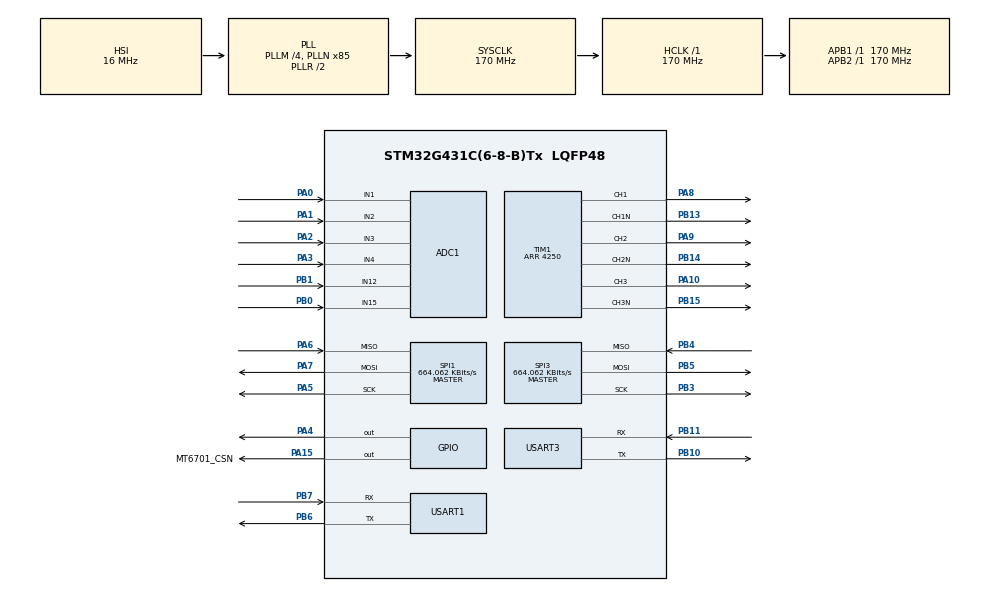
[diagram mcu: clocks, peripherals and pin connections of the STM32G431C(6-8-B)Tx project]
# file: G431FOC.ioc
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ADC1.Channel-0\#ChannelRegularConversion=ADC_CHANNEL_4
ADC1.Channel-4\#ChannelRegularConversion=ADC_CHANNEL_12
ADC1.Channel-5\#ChannelRegularConversion=ADC_CHANNEL_15
ADC1.ContinuousConvMode=ENABLE
ADC1.EOCSelection=ADC_EOC_SEQ_CONV
ADC1.EnableInjectedConversion=ENABLE
ADC1.ExternalTrigInjecConv=ADC_EXTERNALTRIGINJEC_T1_TRGO
ADC1.InjNumberOfConversion=2
ADC1.InjectedChannel-1\#ChannelInjectedConversion=ADC_CHANNEL_1
ADC1.InjectedChannel-2\#ChannelInjectedConversion=ADC_CHANNEL_2
ADC1.InjectedOffsetNumber-1\#ChannelInjectedConversion=ADC_OFFSET_NONE
ADC1.InjectedOffsetNumber-2\#ChannelInjectedConversion=ADC_OFFSET_NONE
ADC1.InjectedRank-1\#ChannelInjectedConversion=1
ADC1.InjectedRank-2\#ChannelInjectedConversion=2
ADC1.InjectedSamplingTime-1\#ChannelInjectedConversion=ADC_SAMPLETIME_47CYCLES_5
ADC1.InjectedSamplingTime-2\#ChannelInjectedConversion=ADC_SAMPLETIME_47CYCLES_5
ADC1.NbrOfConversion=3
ADC1.NbrOfConversionFlag=1
ADC1.OffsetNumber-0\#ChannelRegularConversion=ADC_OFFSET_NONE
ADC1.OffsetNumber-4\#ChannelRegularConversion=ADC_OFFSET_NONE
ADC1.OffsetNumber-5\#ChannelRegularConversion=ADC_OFFSET_NONE
ADC1.Rank-0\#ChannelRegularConversion=1
ADC1.Rank-4\#ChannelRegularConversion=2
ADC1.Rank-5\#ChannelRegularConversion=3
ADC1.SamplingTime-0\#ChannelRegularConversion=ADC_SAMPLETIME_47CYCLES_5
ADC1.SamplingTime-4\#ChannelRegularConversion=ADC_SAMPLETIME_47CYCLES_5
ADC1.SamplingTime-5\#ChannelRegularConversion=ADC_SAMPLETIME_47CYCLES_5
ADC1.master=1
Dma.ADC1.0.Direction=DMA_PERIPH_TO_MEMORY
Dma.ADC1.0.EventEnable=DISABLE
Dma.ADC1.0.Instance=DMA1_Channel1
Dma.ADC1.0.MemDataAlignment=DMA_MDATAALIGN_HALFWORD
Dma.ADC1.0.MemInc=DMA_MINC_ENABLE
Dma.ADC1.0.Mode=DMA_CIRCULAR
Dma.ADC1.0.PeriphDataAlignment=DMA_PDATAALIGN_HALFWORD
Dma.ADC1.0.PeriphInc=DMA_PINC_DISABLE
Dma.ADC1.0.Polarity=HAL_DMAMUX_REQ_GEN_RISING
Dma.ADC1.0.Priority=DMA_PRIORITY_LOW
Dma.ADC1.0.RequestNumber=1
Dma.ADC1.0.SignalID=NONE
Dma.ADC1.0.SyncEnable=DISABLE
Dma.ADC1.0.SyncPolarity=HAL_DMAMUX_SYNC_NO_EVENT
Dma.ADC1.0.SyncRequestNumber=1
Dma.ADC1.0.SyncSignalID=NONE
Dma.Request0=ADC1
Dma.Request1=SPI1_RX
Dma.Request2=SPI1_TX
Dma.Request3=SPI3_RX
Dma.Request4=SPI3_TX
Dma.SPI1_RX.1.Direction=DMA_PERIPH_TO_MEMORY
Dma.SPI1_RX.1.EventEnable=DISABLE
Dma.SPI1_RX.1.Instance=DMA1_Channel2
Dma.SPI1_RX.1.MemDataAlignment=DMA_MDATAALIGN_BYTE
Dma.SPI1_RX.1.MemInc=DMA_MINC_ENABLE
Dma.SPI1_RX.1.Mode=DMA_NORMAL
Dma.SPI1_RX.1.PeriphDataAlignment=DMA_PDATAALIGN_BYTE
Dma.SPI1_RX.1.PeriphInc=DMA_PINC_DISABLE
Dma.SPI1_RX.1.Polarity=HAL_DMAMUX_REQ_GEN_RISING
Dma.SPI1_RX.1.Priority=DMA_PRIORITY_LOW
Dma.SPI1_RX.1.RequestNumber=1
Dma.SPI1_RX.1.SignalID=NONE
Dma.SPI1_RX.1.SyncEnable=DISABLE
Dma.SPI1_RX.1.SyncPolarity=HAL_DMAMUX_SYNC_NO_EVENT
Dma.SPI1_RX.1.SyncRequestNumber=1
Dma.SPI1_RX.1.SyncSignalID=NONE
Dma.SPI1_TX.2.Direction=DMA_MEMORY_TO_PERIPH
Dma.SPI1_TX.2.EventEnable=DISABLE
Dma.SPI1_TX.2.Instance=DMA1_Channel3
Dma.SPI1_TX.2.MemDataAlignment=DMA_MDATAALIGN_BYTE
Dma.SPI1_TX.2.MemInc=DMA_MINC_ENABLE
Dma.SPI1_TX.2.Mode=DMA_NORMAL
Dma.SPI1_TX.2.PeriphDataAlignment=DMA_PDATAALIGN_BYTE
Dma.SPI1_TX.2.PeriphInc=DMA_PINC_DISABLE
Dma.SPI1_TX.2.Polarity=HAL_DMAMUX_REQ_GEN_RISING
Dma.SPI1_TX.2.Priority=DMA_PRIORITY_LOW
Dma.SPI1_TX.2.RequestNumber=1
Dma.SPI1_TX.2.SignalID=NONE
Dma.SPI1_TX.2.SyncEnable=DISABLE
Dma.SPI1_TX.2.SyncPolarity=HAL_DMAMUX_SYNC_NO_EVENT
Dma.SPI1_TX.2.SyncRequestNumber=1
Dma.SPI1_TX.2.SyncSignalID=NONE
Dma.SPI3_RX.3.Direction=DMA_PERIPH_TO_MEMORY
Dma.SPI3_RX.3.EventEnable=DISABLE
Dma.SPI3_RX.3.Instance=DMA1_Channel4
Dma.SPI3_RX.3.MemDataAlignment=DMA_MDATAALIGN_BYTE
Dma.SPI3_RX.3.MemInc=DMA_MINC_ENABLE
Dma.SPI3_RX.3.Mode=DMA_NORMAL
Dma.SPI3_RX.3.PeriphDataAlignment=DMA_PDATAALIGN_BYTE
Dma.SPI3_RX.3.PeriphInc=DMA_PINC_DISABLE
Dma.SPI3_RX.3.Polarity=HAL_DMAMUX_REQ_GEN_RISING
Dma.SPI3_RX.3.Priority=DMA_PRIORITY_LOW
Dma.SPI3_RX.3.RequestNumber=1
Dma.SPI3_RX.3.SignalID=NONE
Dma.SPI3_RX.3.SyncEnable=DISABLE
Dma.SPI3_RX.3.SyncPolarity=HAL_DMAMUX_SYNC_NO_EVENT
Dma.SPI3_RX.3.SyncRequestNumber=1
Dma.SPI3_RX.3.SyncSignalID=NONE
Dma.SPI3_TX.4.Direction=DMA_MEMORY_TO_PERIPH
Dma.SPI3_TX.4.EventEnable=DISABLE
Dma.SPI3_TX.4.Instance=DMA1_Channel5
Dma.SPI3_TX.4.MemDataAlignment=DMA_MDATAALIGN_BYTE
Dma.SPI3_TX.4.MemInc=DMA_MINC_ENABLE
Dma.SPI3_TX.4.Mode=DMA_NORMAL
Dma.SPI3_TX.4.PeriphDataAlignment=DMA_PDATAALIGN_BYTE
Dma.SPI3_TX.4.PeriphInc=DMA_PINC_DISABLE
Dma.SPI3_TX.4.Polarity=HAL_DMAMUX_REQ_GEN_RISING
Dma.SPI3_TX.4.Priority=DMA_PRIORITY_LOW
Dma.SPI3_TX.4.RequestNumber=1
Dma.SPI3_TX.4.SignalID=NONE
Dma.SPI3_TX.4.SyncEnable=DISABLE
Dma.SPI3_TX.4.SyncPolarity=HAL_DMAMUX_SYNC_NO_EVENT
Dma.SPI3_TX.4.SyncRequestNumber=1
Dma.SPI3_TX.4.SyncSignalID=NONE
Mcu.Family=STM32G4
Mcu.Name=STM32G431C(6-8-B)Tx
Mcu.Package=LQFP48
NVIC.ADC1_2_IRQn=true\:0\:0\:false\:false\:true\:true\:true\:true
NVIC.DMA1_Channel1_IRQn=true\:0\:0\:false\:false\:true\:false\:true\:true
NVIC.DMA1_Channel2_IRQn=true\:1\:0\:false\:false\:true\:false\:true\:true
NVIC.DMA1_Channel3_IRQn=true\:1\:0\:false\:false\:true\:false\:true\:true
NVIC.DMA1_Channel4_IRQn=true\:1\:0\:false\:false\:true\:false\:true\:true
NVIC.DMA1_Channel5_IRQn=true\:1\:0\:false\:false\:true\:false\:true\:true
NVIC.PriorityGroup=NVIC_PRIORITYGROUP_4
NVIC.SPI1_IRQn=true\:1\:0\:false\:false\:true\:true\:true\:true
NVIC.SPI3_IRQn=true\:1\:0\:false\:false\:true\:true\:true\:true
NVIC.TIM2_IRQn=true\:0\:0\:false\:false\:true\:true\:true\:true
PA0.Mode=IN1-Single-Ended
PA0.Signal=ADC1_IN1
PA1.Mode=IN2-Single-Ended
PA1.Signal=ADC1_IN2
PA10.Signal=S_TIM1_CH3
PA13.Mode=Serial_Wire
PA13.Signal=SYS_JTMS-SWDIO
PA14.Mode=Serial_Wire
PA14.Signal=SYS_JTCK-SWCLK
PA15.GPIO_Label=MT6701_CSN
PA15.PinState=GPIO_PIN_SET
PA15.Signal=GPIO_Output
PA2.Mode=IN3-Single-Ended
PA2.Signal=ADC1_IN3
PA3.Mode=IN4-Single-Ended
PA3.Signal=ADC1_IN4
PA4.PinState=GPIO_PIN_SET
PA4.Signal=GPIO_Output
PA5.Mode=Full_Duplex_Master
PA5.Signal=SPI1_SCK
PA6.Mode=Full_Duplex_Master
PA6.Signal=SPI1_MISO
PA7.Mode=Full_Duplex_Master
PA7.Signal=SPI1_MOSI
PA8.Signal=S_TIM1_CH1
PA9.Signal=S_TIM1_CH2
PB0.Mode=IN15-Single-Ended
PB0.Signal=ADC1_IN15
PB1.Mode=IN12-Single-Ended
PB1.Signal=ADC1_IN12
PB10.Mode=Asynchronous
PB10.Signal=USART3_TX
PB11.Mode=Asynchronous
PB11.Signal=USART3_RX
PB13.Mode=PWM Generation1 CH1 CH1N
PB13.Signal=TIM1_CH1N
PB14.Mode=PWM Generation2 CH2 CH2N
PB14.Signal=TIM1_CH2N
PB15.Mode=PWM Generation3 CH3 CH3N
PB15.Signal=TIM1_CH3N
PB3.Mode=Full_Duplex_Master
PB3.Signal=SPI3_SCK
PB4.Mode=Full_Duplex_Master
PB4.Signal=SPI3_MISO
PB5.Mode=Full_Duplex_Master
PB5.Signal=SPI3_MOSI
PB6.Mode=Asynchronous
PB6.Signal=USART1_TX
PB7.Mode=Asynchronous
PB7.Signal=USART1_RX
PF0-OSC_IN.Mode=HSE-External-Oscillator
PF0-OSC_IN.Signal=RCC_OSC_IN
PF1-OSC_OUT.Mode=HSE-External-Oscillator
PF1-OSC_OUT.Signal=RCC_OSC_OUT
ProjectManager.HeapSize=0x200
ProjectManager.StackSize=0x400
ProjectManager.TargetToolchain=MDK-ARM V5.32
RCC.ADC12Freq_Value=170000000
RCC.AHBFreq_Value=170000000
RCC.APB1Freq_Value=170000000
RCC.APB1TimFreq_Value=170000000
RCC.APB2Freq_Value=170000000
RCC.APB2TimFreq_Value=170000000
RCC.CortexFreq_Value=170000000
RCC.EXTERNAL_CLOCK_VALUE=12288000
RCC.HCLKFreq_Value=170000000
RCC.HSE_VALUE=8000000
RCC.HSI48_VALUE=48000000
RCC.HSI_VALUE=16000000
RCC.LSE_VALUE=32768
RCC.PLLM=RCC_PLLM_DIV4
RCC.PLLN=85
RCC.SYSCLKFreq_VALUE=170000000
RCC.SYSCLKSource=RCC_SYSCLKSOURCE_PLLCLK
RCC.USBFreq_Value=170000000
RCC.VCOOutputFreq_Value=340000000
SH.S_TIM1_CH1.0=TIM1_CH1,PWM Generation1 CH1 CH1N
SH.S_TIM1_CH2.0=TIM1_CH2,PWM Generation2 CH2 CH2N
SH.S_TIM1_CH3.0=TIM1_CH3,PWM Generation3 CH3 CH3N
SPI1.BaudRatePrescaler=SPI_BAUDRATEPRESCALER_256
SPI1.CLKPhase=SPI_PHASE_2EDGE
SPI1.CalculateBaudRate=664.062 KBits/s
SPI1.DataSize=SPI_DATASIZE_8BIT
SPI1.Direction=SPI_DIRECTION_2LINES
SPI1.Mode=SPI_MODE_MASTER
SPI1.VirtualType=VM_MASTER
SPI3.BaudRatePrescaler=SPI_BAUDRATEPRESCALER_256
SPI3.CLKPhase=SPI_PHASE_2EDGE
SPI3.CalculateBaudRate=664.062 KBits/s
SPI3.DataSize=SPI_DATASIZE_8BIT
SPI3.Direction=SPI_DIRECTION_2LINES
SPI3.Mode=SPI_MODE_MASTER
SPI3.VirtualType=VM_MASTER
STMicroelectronics.X-CUBE-ALGOBUILD.1.5.0.LibraryCcDSPOoLibraryJjDSPOoLibrary=true
TIM1.AutoReloadPreload=TIM_AUTORELOAD_PRELOAD_ENABLE
TIM1.Channel-PWM\ Generation1\ CH1\ CH1N=TIM_CHANNEL_1
TIM1.Channel-PWM\ Generation2\ CH2\ CH2N=TIM_CHANNEL_2
TIM1.Channel-PWM\ Generation3\ CH3\ CH3N=TIM_CHANNEL_3
TIM1.CounterMode=TIM_COUNTERMODE_CENTERALIGNED1
TIM1.DeadTime=25
TIM1.OCNPolarity_1=TIM_OCNPOLARITY_HIGH
TIM1.OCNPolarity_2=TIM_OCNPOLARITY_HIGH
TIM1.OCNPolarity_3=TIM_OCNPOLARITY_HIGH
TIM1.OCPolarity_1=TIM_OCPOLARITY_HIGH
TIM1.OCPolarity_2=TIM_OCPOLARITY_HIGH
TIM1.OCPolarity_3=TIM_OCPOLARITY_HIGH
TIM1.PeriodNoDither=4250
TIM1.TIM_MasterOutputTrigger=TIM_TRGO_UPDATE
TIM2.AutoReloadPreload=TIM_AUTORELOAD_PRELOAD_ENABLE
TIM2.PeriodNoDither=17000-1
TIM2.Prescaler=9
USART1.VirtualMode-Asynchronous=VM_ASYNC
USART3.VirtualMode-Asynchronous=VM_ASYNC
VP_STMicroelectronics.X-CUBE-ALGOBUILD_VS_DSPOoLibraryJjLibrary_1.5.0_1.5.0.Mode=DSPOoLibraryJjLibrary
VP_SYS_VS_DBSignals.Mode=DisableDeadBatterySignals
VP_TIM1_VS_ClockSourceINT.Mode=Internal
VP_TIM2_VS_ClockSourceINT.Mode=Internal
board=custom

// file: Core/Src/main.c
/* USER CODE BEGIN Header */
/**
  ******************************************************************************
  * @file           : main.c
  * @brief          : Main program body
  ******************************************************************************
  * @attention
  *
  * Copyright (c) 2026 STMicroelectronics.
  * All rights reserved.
  *
  * This software is licensed under terms that can be found in the LICENSE file
  * in the root directory of this software component.
  * If no LICENSE file comes with this software, it is provided AS-IS.
  *
  ******************************************************************************
  */
/* USER CODE END Header */
#include "main.h"
#include "adc.h"
#include "dma.h"
#include "spi.h"
#include "tim.h"
#include "usart.h"
#include "gpio.h"

/* USER CODE BEGIN Includes */
#include "foc_app.h"

/* USER CODE END Includes */

void SystemClock_Config(void);

int main(void)
{

  /* MCU Configuration--------------------------------------------------------*/

  /* Reset of all peripherals, Initializes the Flash interface and the Systick. */
  HAL_Init();

  /* Configure the system clock */
  SystemClock_Config();

  /* Initialize all configured peripherals */
  MX_GPIO_Init();
  MX_DMA_Init();
  MX_ADC1_Init();
  MX_SPI1_Init();
  MX_SPI3_Init();
  MX_TIM1_Init();
  MX_TIM2_Init();
  MX_USART1_UART_Init();
  MX_USART3_UART_Init();
  /* USER CODE BEGIN 2 */
  FocApp_Init();
  /* USER CODE END 2 */

  /* Infinite loop */
  /* USER CODE BEGIN WHILE */
  while (1)
  {
    FocApp_Tick();
    /* USER CODE END WHILE */

  }
}

void SystemClock_Config(void)
{
  RCC_OscInitTypeDef RCC_OscInitStruct = {0};
  RCC_ClkInitTypeDef RCC_ClkInitStruct = {0};

  /** Configure the main internal regulator output voltage
  */
  HAL_PWREx_ControlVoltageScaling(PWR_REGULATOR_VOLTAGE_SCALE1_BOOST);

  /** Initializes the RCC Oscillators according to the specified parameters
  * in the RCC_OscInitTypeDef structure.
  */
  RCC_OscInitStruct.OscillatorType = RCC_OSCILLATORTYPE_HSI;
  RCC_OscInitStruct.HSIState = RCC_HSI_ON;
  RCC_OscInitStruct.HSICalibrationValue = RCC_HSICALIBRATION_DEFAULT;
  RCC_OscInitStruct.PLL.PLLState = RCC_PLL_ON;
  RCC_OscInitStruct.PLL.PLLSource = RCC_PLLSOURCE_HSI;
  RCC_OscInitStruct.PLL.PLLM = RCC_PLLM_DIV4;
  RCC_OscInitStruct.PLL.PLLN = 85;
  RCC_OscInitStruct.PLL.PLLP = RCC_PLLP_DIV2;
  RCC_OscInitStruct.PLL.PLLQ = RCC_PLLQ_DIV2;
  RCC_OscInitStruct.PLL.PLLR = RCC_PLLR_DIV2;
  if (HAL_RCC_OscConfig(&RCC_OscInitStruct) != HAL_OK)
  {
    Error_Handler();
  }

  /** Initializes the CPU, AHB and APB buses clocks
  */
  RCC_ClkInitStruct.ClockType = RCC_CLOCKTYPE_HCLK|RCC_CLOCKTYPE_SYSCLK
                              |RCC_CLOCKTYPE_PCLK1|RCC_CLOCKTYPE_PCLK2;
  RCC_ClkInitStruct.SYSCLKSource = RCC_SYSCLKSOURCE_PLLCLK;
  RCC_ClkInitStruct.AHBCLKDivider = RCC_SYSCLK_DIV1;
  RCC_ClkInitStruct.APB1CLKDivider = RCC_HCLK_DIV1;
  RCC_ClkInitStruct.APB2CLKDivider = RCC_HCLK_DIV1;

  if (HAL_RCC_ClockConfig(&RCC_ClkInitStruct, FLASH_LATENCY_4) != HAL_OK)
  {
    Error_Handler();
  }
}

void Error_Handler(void)
{
  __disable_irq();
  while (1)
  {
  }
}
